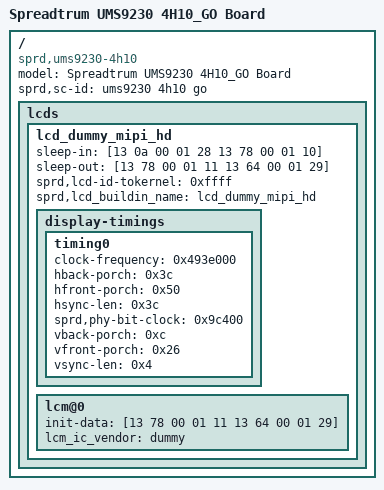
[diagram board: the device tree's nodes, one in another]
/dts-v1/;

/ {
	compatible = "sprd,ums9230-4h10";
	model = "Spreadtrum UMS9230 4H10_GO Board";
	sprd,sc-id = "ums9230 4h10 go";

	__fixups__ {
		adi_bus = "/fragment@32:target:0";
		aon_clk = "/fragment/__overlay__/sprd-marlin3:clocks:0";
		aon_i2c0 = "/fragment@8:target:0";
		aonapb_gate = "/fragment/__overlay__/sprd-marlin3:clocks:12";
		ap_gpio = "/fragment/__overlay__/gpio-keys/key-volumedown:gpios:0", "/fragment/__overlay__/audio-voice-trig:irq_gpio:0", "/fragment/__overlay__/sprd-marlin3:m2-wakeup-ap-gpios:0", "/fragment/__overlay__/sprd-marlin3:reset-gpios:0", "/fragment/__overlay__/sprd-marlin3:enable-gpios:0", "/fragment/__overlay__/sprd-marlin3:m2-to-ap-irq-gpios:0", "/fragment@4/__overlay__/sensor-main@20:dvdd-gpios:0", "/fragment@4/__overlay__/sensor-main@20:reset-gpios:0", "/fragment@4/__overlay__/sensor-main@20:power-down-gpios:0", "/fragment@4/__overlay__/sensor-sub@5a:dvdd-gpios:0", "/fragment@4/__overlay__/sensor-sub@5a:reset-gpios:0", "/fragment@4/__overlay__/sensor-sub@5a:power-down-gpios:0", "/fragment@5/__overlay__/sensor-main2@20:mot-gpios:0", "/fragment@5/__overlay__/sensor-main2@20:reset-gpios:0", "/fragment@5/__overlay__/sensor-main2@20:power-down-gpios:0", "/fragment@6/__overlay__/charger@6b:irq-gpio:0", "/fragment@6/__overlay__/charger@65:irq-gpio:0", "/fragment@6/__overlay__/charger@1b:chg_pump_en_gpio:0", "/fragment@6/__overlay__/charger@61:rx,irq_gpio:0", "/fragment@6/__overlay__/charger@61:switch_chg_en_gpio:0", "/fragment@6/__overlay__/charger@61:switch_flag_en_gpio:0", "/fragment@6/__overlay__/flash-ic@63:flash-torch-en-gpios:0", "/fragment@6/__overlay__/flash-ic@63:flash-chip-en-gpios:0", "/fragment@6/__overlay__/flash-ic@63:flash-en-gpios:0", "/fragment@6/__overlay__/flash-ic@63:flash-sync-gpios:0", "/fragment@7/__overlay__/sensor-sub2@6e:avdd-gpios:0", "/fragment@7/__overlay__/sensor-sub2@6e:mot-gpios:0", "/fragment@7/__overlay__/sensor-sub2@6e:reset-gpios:0", "/fragment@9/__overlay__/focaltech@0:focaltech,reset-gpio:0", "/fragment@9/__overlay__/focaltech@0:focaltech,irq-gpio:0", "/fragment@17/__overlay__/ucp1301@58:reset-gpios:0", "/fragment@19/__overlay__/ucp1301@58:reset-gpios:0", "/fragment@20/__overlay__:mic-gpios:0", "/fragment@20/__overlay__:lr-gpios:0", "/fragment@25/__overlay__:avdd-gpio:0", "/fragment@25/__overlay__:avee-gpio:0", "/fragment@25/__overlay__:reset-gpio:0";
		chosen = "/fragment@1:target:0";
		csi0 = "/fragment@4/__overlay__/sensor-main@20:csi:0", "/fragment@4/__overlay__/sensor-sub@5a:csi:0";
		csi1 = "/fragment@5/__overlay__/sensor-main2@20:csi:0";
		csi2 = "/fragment@7/__overlay__/sensor-sub2@6e:csi:0";
		ddr_dfs = "/fragment@29:target:0";
		dpu = "/fragment@26:target:0";
		dvfs_dcdc_cpu0_supply = "/fragment@10:target:0";
		dvfs_dcdc_cpu1_supply = "/fragment@11:target:0";
		eic_async = "/fragment/__overlay__/fingerprint@0:fpint-gpios:0";
		eic_sync = "/fragment@14/__overlay__:cd-gpios:0";
		ext_26m = "/fragment@4/__overlay__/sensor-main@20:clocks:40", "/fragment@4/__overlay__/sensor-sub@5a:clocks:40", "/fragment@5/__overlay__/sensor-main2@20:clocks:40", "/fragment@7/__overlay__/sensor-sub2@6e:clocks:40";
		ext_32k = "/fragment/__overlay__/sprd-marlin3:clocks:8";
		extcon_gpio = "/fragment@6/__overlay__/charger@6b:extcon:0", "/fragment@12/__overlay__:extcon:0", "/fragment@13/__overlay__:extcon:0";
		hsphy = "/fragment@6/__overlay__/charger@6b:phys:0", "/fragment@6/__overlay__/charger@61:phys:0", "/fragment@12:target:0", "/fragment@27/__overlay__:phys:0";
		i2c0 = "/fragment@4:target:0";
		i2c1 = "/fragment@5:target:0";
		i2c2 = "/fragment@17:target:0";
		i2c3 = "/fragment@18:target:0";
		i2c4 = "/fragment@19:target:0";
		i2c5 = "/fragment@6:target:0";
		i2c6 = "/fragment@7:target:0";
		ion = "/fragment@15:target:0", "/fragment@31:target:0";
		mm_clk = "/fragment@4/__overlay__/sensor-main@20:clocks:0", "/fragment@4/__overlay__/sensor-sub@5a:clocks:0", "/fragment@5/__overlay__/sensor-main2@20:clocks:0", "/fragment@7/__overlay__/sensor-sub2@6e:clocks:0";
		mm_gate = "/fragment@4/__overlay__/sensor-main@20:clocks:8", "/fragment@4/__overlay__/sensor-sub@5a:clocks:8", "/fragment@5/__overlay__/sensor-main2@20:clocks:8", "/fragment@7/__overlay__/sensor-sub2@6e:clocks:8";
		panel = "/fragment@25:target:0";
		pdm_dmic = "/fragment@21:target:0", "/fragment@22/__overlay__/sprd-audio-card,dai-link@81/codec:sound-dai:0";
		pin_controller = "/fragment@30:target:0";
		pll1 = "/fragment@4/__overlay__/sensor-main@20:clocks:16", "/fragment@4/__overlay__/sensor-main@20:clocks:24", "/fragment@4/__overlay__/sensor-main@20:clocks:32", "/fragment@4/__overlay__/sensor-sub@5a:clocks:16", "/fragment@4/__overlay__/sensor-sub@5a:clocks:24", "/fragment@4/__overlay__/sensor-sub@5a:clocks:32", "/fragment@5/__overlay__/sensor-main2@20:clocks:16", "/fragment@5/__overlay__/sensor-main2@20:clocks:24", "/fragment@5/__overlay__/sensor-main2@20:clocks:32", "/fragment@7/__overlay__/sensor-sub2@6e:clocks:16", "/fragment@7/__overlay__/sensor-sub2@6e:clocks:24", "/fragment@7/__overlay__/sensor-sub2@6e:clocks:32";
		pmic_adc = "/fragment/__overlay__/thermal-sensor:io-channels:0", "/fragment/__overlay__/pa-sensor:io-channels:0", "/fragment/__overlay__/chg-sensor:io-channels:0";
		pmic_eic = "/fragment/__overlay__/gpio-keys/key-volumeup:gpios:0", "/fragment/__overlay__/gpio-keys/key-power:gpios:0";
		pmic_fchg = "/fragment@27:target:0";
		pmic_fgu = "/fragment@24:target:0";
		pmic_pd = "/fragment@6/__overlay__/charger@6b:extcon:4", "/fragment@28:target:0";
		pmic_typec = "/fragment/__overlay__/charger-manager/regulator@0/cable@0:extcon:0", "/fragment@13/__overlay__:extcon:4", "/fragment@20/__overlay__:extcon:0";
		pwms = "/fragment/__overlay__/sprd_backlight:pwms:0";
		reserved_memory = "/fragment@2:target:0";
		sdio0 = "/fragment@14:target:0";
		sdio1 = "/fragment/__overlay__/sprd-marlin3:sdhci-name:0", "/fragment@0:target:0";
		sound_vbc_v4_sprd_codec = "/fragment@22:target:0";
		spi3 = "/fragment@9:target:0";
		sprd_headset = "/fragment@20:target:0";
		sprd_route_pcm = "/fragment@22/__overlay__/sprd-audio-card,dai-link@53/plat:sound-dai:0", "/fragment@22/__overlay__/sprd-audio-card,dai-link@55/plat:sound-dai:0", "/fragment@22/__overlay__/sprd-audio-card,dai-link@81/plat:sound-dai:0";
		thm_zone = "/fragment@3:target:0";
		ufs = "/fragment@16:target:0";
		uid_end = "/fragment/__overlay__/sprd_uid:nvmem-cells:4";
		uid_start = "/fragment/__overlay__/sprd_uid:nvmem-cells:0";
		usb = "/fragment@13:target:0";
		vbc_v4 = "/fragment@22/__overlay__/sprd-audio-card,dai-link@53/cpu:sound-dai:0", "/fragment@22/__overlay__/sprd-audio-card,dai-link@55/cpu:sound-dai:0", "/fragment@22/__overlay__/sprd-audio-card,dai-link@81/cpu:sound-dai:0";
		vddcama0 = "/fragment@4/__overlay__/sensor-main@20:vddcama-supply:0", "/fragment@4/__overlay__/sensor-sub@5a:vddcama-supply:0";
		vddcama1 = "/fragment@5/__overlay__/sensor-main2@20:vddcama-supply:0";
		vddcamd0 = "/fragment@5/__overlay__/sensor-main2@20:vddcamd-supply:0";
		vddcamd1 = "/fragment@7/__overlay__/sensor-sub2@6e:vddcamd-supply:0";
		vddcamio = "/fragment@4/__overlay__/sensor-main@20:vddio-supply:0", "/fragment@4/__overlay__/sensor-sub@5a:vddio-supply:0", "/fragment@5/__overlay__/sensor-main2@20:vddio-supply:0", "/fragment@7/__overlay__/sensor-sub2@6e:vddio-supply:0";
		vddcammot = "/fragment@4/__overlay__/sensor-main@20:vddcammot-supply:0", "/fragment@4/__overlay__/sensor-sub@5a:vddcammot-supply:0", "/fragment@5/__overlay__/sensor-main2@20:vddcammot-supply:0", "/fragment@7/__overlay__/sensor-sub2@6e:vddcammot-supply:0";
		vddldo0 = "/fragment@23:target:0";
		vddsim2 = "/fragment/__overlay__/sprd-marlin3:dcxo18-supply:0";
		vddusb33 = "/fragment@12/__overlay__:vdd-supply:0";
		vddwcn = "/fragment/__overlay__/sprd-marlin3:avdd12-supply:0";
		vddwifipa = "/fragment/__overlay__/sprd-marlin3:avdd33-supply:0";
	};

	__local_fixups__ {

		fragment {

			__overlay__ {

				charger-manager {
					monitored-battery = <0x0>;
				};

				lcds {

					lcd_g40396_truly_mipi_fhd {

						display-timings {
							native-mode = <0x0>;
						};
					};
				};
			};
		};

		fragment@13 {

			__overlay__ {
				vbus-supply = <0x0>;
			};
		};

		fragment@15 {

			__overlay__ {

				heap@3 {
					memory-region = <0x0>;
				};
			};
		};

		fragment@22 {

			__overlay__ {

				sprd-audio-card,dai-link@53 {

					codec {
						sound-dai = <0x0>;
					};
				};

				sprd-audio-card,dai-link@55 {

					codec {
						sound-dai = <0x0>;
					};
				};
			};
		};

		fragment@24 {

			__overlay__ {
				monitored-battery = <0x0>;
			};
		};

		fragment@25 {

			__overlay__ {
				sprd,backlight = <0x0>;
			};
		};

		fragment@26 {

			__overlay__ {
				sprd,backlight = <0x0>;
				sprd,logo-memory = <0x0>;
				sprd,wb-memory = <0x0>;
			};
		};

		fragment@3 {

			__overlay__ {

				board-thmzone {
					thermal-sensors = <0x0>;
				};

				chg-thmzone {
					thermal-sensors = <0x0>;
				};

				pa-thmzone {
					thermal-sensors = <0x0>;
				};
			};
		};

		fragment@30 {

			__overlay__ {
				pinctrl-0 = <0x0>;
				pinctrl-1 = <0x0>;
				pinctrl-2 = <0x0>;
				pinctrl-3 = <0x0>;
				pinctrl-4 = <0x0>;
				pinctrl-5 = <0x0>;
				pinctrl-6 = <0x0>;
			};
		};

		fragment@31 {

			__overlay__ {

				heap@4 {
					memory-region = <0x0>;
				};
			};
		};

		fragment@6 {

			__overlay__ {

				charger@6b {
					monitored-battery = <0x0>;
				};
			};
		};
	};

	__symbols__ {
		bat = "/fragment/__overlay__/battery";
		bd_thmzone = "/fragment@3/__overlay__/board-thmzone";
		bq2560x_chg = "/fragment@6/__overlay__/charger@6b";
		bq2597x_chg = "/fragment@6/__overlay__/charger@65";
		chg_thermistor = "/fragment/__overlay__/chg-sensor";
		chg_thmzone = "/fragment@3/__overlay__/chg-thmzone";
		fb_reserved = "/fragment@2/__overlay__/framebuffer-mem@fe980000";
		fd_reserved = "/fragment@2/__overlay__/faceid-mem@fd9a0000";
		flash_ic = "/fragment@6/__overlay__/flash-ic@63";
		g40396_truly_timing0 = "/fragment/__overlay__/lcds/lcd_g40396_truly_mipi_fhd/display-timings/timing0";
		gpio_124 = "/fragment@30/__overlay__/keyin0";
		gpio_175 = "/fragment@30/__overlay__/bt_rfctl2";
		gpio_22 = "/fragment@30/__overlay__/rfctl3";
		gpio_24 = "/fragment@30/__overlay__/rfctl5";
		gpio_25 = "/fragment@30/__overlay__/rfctl6";
		gpio_26 = "/fragment@30/__overlay__/rfctl7";
		gpio_8 = "/fragment@30/__overlay__/rfctl16";
		hl1506_cp_converter = "/fragment@6/__overlay__/charger@1b";
		lcd_dummy_mipi_hd = "/lcds/lcd_dummy_mipi_hd";
		lcd_dummy_timing0 = "/lcds/lcd_dummy_mipi_hd/display-timings/timing0";
		lcd_g40396_truly_mipi_fhd = "/fragment/__overlay__/lcds/lcd_g40396_truly_mipi_fhd";
		logo_reserved = "/fragment@2/__overlay__/logobuffer@9e000000";
		nu1619_rx = "/fragment@6/__overlay__/charger@61";
		pa_thermistor = "/fragment/__overlay__/pa-sensor";
		pa_thmzone = "/fragment@3/__overlay__/pa-thmzone";
		pwm_backlight = "/fragment/__overlay__/sprd_backlight";
		sensor_main = "/fragment@4/__overlay__/sensor-main@20";
		sensor_main2 = "/fragment@5/__overlay__/sensor-main2@20";
		sensor_sub = "/fragment@4/__overlay__/sensor-sub@5a";
		sensor_sub2 = "/fragment@7/__overlay__/sensor-sub2@6e";
		sprd_marlin3 = "/fragment/__overlay__/sprd-marlin3";
		tboard_thermistor = "/fragment/__overlay__/thermal-sensor";
		ucp1301_rcv = "/fragment@17/__overlay__/ucp1301@58";
		ucp1301_spk = "/fragment@19/__overlay__/ucp1301@58";
		usb_con = "/fragment@28/__overlay__/connector";
		vddvbus = "/fragment@6/__overlay__/charger@6b/otg-vbus";
		wb_reserved = "/fragment@2/__overlay__/writeback-mem@fdea0000";
	};

	fragment {
		target-path = [2f 00];

		__overlay__ {

			audio-voice-trig {
				compatible = "sprd,voice_trig";
				irq_gpio = <0xffffffff 0xa9 0x0>;
				status = "disable";
			};

			battery {
				capacity-temp-table = <0x2d 0x64 0x19 0x64 0xa 0x64 0x0 0x5f 0xfffffff6 0x5a>;
				charge-cdp-current-microamp = <0x16e360 0x16e360>;
				charge-dcp-current-microamp = <0x1e8480 0x2dc6c0>;
				charge-fchg-current-microamp = <0x319750 0x2dc6c0>;
				charge-flash-current-microamp = <0x4c4b40 0x2932e0>;
				charge-full-design-microamp-hours = <0x2d0370>;
				charge-pumps-threshold-microvolt = <0x3e8fa0>;
				charge-sdp-current-microamp = <0x7a120 0x7a120>;
				charge-term-current-microamp = <0xea60>;
				charge-unknown-current-microamp = <0x7a120 0x7a120>;
				charge-wl-bpp-current-microamp = <0xf4240 0xf4240>;
				charge-wl-epp-current-microamp = <0x1e8480 0xf4240>;
				compatible = "simple-battery";
				constant_charge_voltage_max_microvolt = <0x423920>;
				factory-internal-resistance-micro-ohms = <0x3d860>;
				ocv-capacity-celsius = <0x14>;
				ocv-capacity-table-0 = <0x41cfa8 0x64 0x40e930 0x5f 0x401a28 0x5a 0x3f56d8 0x55 0x3e9770 0x50 0x3df360 0x4b 0x3d2070 0x46 0x3c9f88 0x41 0x3bf790 0x3c 0x3b3c10 0x37 0x3ac2f8 0x32 0x3a6d08 0x2d 0x3a22d0 0x28 0x39e838 0x23 0x39b188 0x1e 0x397308 0x19 0x3928d0 0x14 0x38cb10 0xf 0x385db0 0xa 0x382ed0 0x5 0x33e140 0x0>;
				phandle = <0x2>;
				resistance-temp-table = <0x2d 0x35 0x19 0x64 0xa 0x18b 0x0 0x237 0xfffffff6 0x319>;
				voltage-min-design-microvolt = <0x34a490>;
				voltage-temp-table = <0x108a60 0x320 0xee098 0x352 0xd3ea0 0x384 0xbac48 0x3b6 0xa3160 0x3e8 0x8d9a0 0x41a 0x7a508 0x44c 0x68fb0 0x47e 0x5a168 0x4b0 0x4ce78 0x4e2 0x41eb0 0x514 0x38658 0x546 0x30188 0x578 0x29428 0x5aa 0x23668 0x5dc 0x1e848 0x60e 0x1a5e0 0x640 0x16b48 0x672>;
			};

			charger-manager {
				cm-battery-cold = <0xc8>;
				cm-battery-cold-in-minus;
				cm-battery-hot = <0x320>;
				cm-battery-stat = <0x2>;
				cm-battery-temp-diff = <0x64>;
				cm-cap-remap-table = <0x1 0x2 0x3 0x2 0x3 0x2 0x62 0x63 0x2 0x63 0x64 0x3>;
				cm-capacity-track;
				cm-cdp-jeita-temp-table = <0x3e8 0x406 0x0 0x423920 0x47e 0x49c 0xaae60 0x423920 0x5aa 0x58c 0x16e360 0x423920 0x640 0x622 0xaae60 0x3e8fa0>;
				cm-charge-pumps = "bq2597x-standalone";
				cm-charge-voltage-drop = <0xaae60>;
				cm-charge-voltage-max = <0x632ea0>;
				cm-chargers = "bq2560x_charger";
				cm-charging-max = <0x1499700>;
				cm-cp-taper-current = <0xf4240>;
				cm-dcp-jeita-temp-table = <0x3e8 0x406 0x0 0x423920 0x47e 0x49c 0xaae60 0x423920 0x5aa 0x58c 0x1e8480 0x423920 0x640 0x622 0xaae60 0x3e8fa0>;
				cm-discharging-max = <0x2932e0>;
				cm-fast-charge-voltage-drop = <0xaae60>;
				cm-fast-charge-voltage-max = <0xa037a0>;
				cm-fast-chargers = "sc2730_fast_charger";
				cm-fchg-jeita-temp-table = <0x3e8 0x406 0x0 0x423920 0x47e 0x49c 0xaae60 0x423920 0x5aa 0x58c 0x319750 0x423920 0x640 0x622 0xaae60 0x3e8fa0>;
				cm-flash-charge-voltage-drop = <0xf4240>;
				cm-flash-charge-voltage-max = <0xb71b00>;
				cm-flash-jeita-temp-table = <0x3e8 0x406 0x0 0x423920 0x47e 0x49c 0xf4240 0x423920 0x5aa 0x58c 0x4c4b40 0x423920 0x640 0x622 0xf4240 0x3e8fa0>;
				cm-fuel-gauge = "sc27xx-fgu";
				cm-fullbatt-capacity = <0x64>;
				cm-fullbatt-current = <0x1d4c0>;
				cm-fullbatt-vchkdrop-ms = <0x7530>;
				cm-fullbatt-vchkdrop-volt = <0xea60>;
				cm-fullbatt-voltage = <0x419ce0>;
				cm-ir-cv-offset-microvolt = <0x186a0>;
				cm-ir-rc = <0x14>;
				cm-ir-us-upper-limit-microvolt = <0x44aa20>;
				cm-name = "battery";
				cm-num-charge-pumps = <0x1>;
				cm-num-chargers = <0x1>;
				cm-num-fast-chargers = <0x1>;
				cm-num-wireless-charge-pump-converters = <0x1>;
				cm-num-wireless-chargers = <0x1>;
				cm-one-cap-time = <0x1e>;
				cm-poll-interval = <0x3a98>;
				cm-poll-mode = <0x2>;
				cm-sdp-jeita-temp-table = <0x3e8 0x406 0x0 0x423920 0x47e 0x49c 0x7a120 0x423920 0x5aa 0x58c 0x7a120 0x423920 0x640 0x622 0x7a120 0x3e8fa0>;
				cm-shutdown-voltage = <0x2f4d60>;
				cm-tickle-time-out = <0x5dc>;
				cm-unknown-jeita-temp-table = <0x3e8 0x406 0x0 0x423920 0x47e 0x49c 0x7a120 0x423920 0x5aa 0x58c 0x7a120 0x423920 0x640 0x622 0x7a120 0x3e8fa0>;
				cm-wdt-interval = <0x3c>;
				cm-wireless-charge-pump-converters = "hl1506_cp_converter";
				cm-wireless-charge-voltage-drop = <0xaae60>;
				cm-wireless-charge-voltage-max = <0x632ea0>;
				cm-wireless-chargers = "nu1619_wireless_charger";
				cm-wireless-fast-charge-voltage-drop = <0xf4240>;
				cm-wireless-fast-charge-voltage-max = <0xb71b00>;
				cm-wl-bpp-jeita-temp-table = <0x3e8 0x406 0x0 0x423920 0x47e 0x49c 0x7a120 0x423920 0x5aa 0x58c 0xf4240 0x423920 0x640 0x622 0x4c4b40 0x3e8fa0>;
				cm-wl-epp-jeita-temp-table = <0x3e8 0x406 0x0 0x423920 0x47e 0x49c 0x7a120 0x423920 0x5aa 0x58c 0x1e8480 0x423920 0x640 0x622 0x7a120 0x3e8fa0>;
				compatible = "charger-manager";
				monitored-battery = <0x2>;

				regulator@0 {
					cm-regulator-name = "vddgen0";

					cable@0 {
						cm-cable-name = "USB";
						extcon = <0xffffffff>;
					};
				};
			};

			chg-sensor {
				#thermal-sensor-cells = <0x0>;
				compatible = "generic-adc-thermal";
				io-channel-names = "sensor-channel";
				io-channels = <0xffffffff 0x4>;
				phandle = <0x5>;
				temperature-lookup-table = <0xffff64c2 0x46b 0xffff8baf 0x456 0xffffb3e8 0x432 0xffffedb9 0x3d7 0x277e 0x346 0x60e5 0x28e 0xaf7a 0x19d 0xd677 0x13c 0xfd7f 0xee 0x12484 0xb2 0x14b93 0x85 0x172a3 0x64 0x199b0 0x4b 0x1c0c9 0x39 0x1e7c8 0x2b>;
			};

			fingerprint@0 {
				compatible = "microarray,afs121";
				fpint-gpios = <0xffffffff 0x1d 0x0>;
			};

			gnss_common_ctl {
				compatible = "sprd,gnss_common_ctl";
				sprd,name = "gnss_common_ctl";
			};

			gpio-keys {
				compatible = "gpio-keys";

				key-power {
					debounce-interval = <0x2>;
					gpios = <0xffffffff 0x1 0x1>;
					label = "Power Key";
					linux,code = <0x74>;
					wakeup-source;
				};

				key-volumedown {
					debounce-interval = <0x2>;
					gpios = <0xffffffff 0x7c 0x1>;
					label = "Volume Down Key";
					linux,code = <0x72>;
					wakeup-source;
				};

				key-volumeup {
					debounce-interval = <0x2>;
					gpios = <0xffffffff 0x4 0x0>;
					label = "Volume Up Key";
					linux,code = <0x73>;
					wakeup-source;
				};
			};

			lcds {

				lcd_g40396_truly_mipi_fhd {
					phandle = <0x15>;
					sprd,dpi-clk-div = <0x6>;
					sprd,dsi-color-format = "rgb888";
					sprd,dsi-lane-number = <0x4>;
					sprd,dsi-work-mode = <0x1>;
					sprd,esd-check-enable = <0x1>;
					sprd,esd-check-mode = <0x0>;
					sprd,esd-check-period = <0x7d0>;
					sprd,esd-check-regs = <0xa>;
					sprd,esd-return-code = <0x9c>;
					sprd,height-mm = <0x98>;
					sprd,hporch-lp-disable = <0x1>;
					sprd,initial-command = [29 00 00 02 00 00 29 00 00 04 ff 87 56 01 29 00 00 02 00 80 29 00 00 03 ff 87 56 29 00 00 02 00 a1 29 00 00 07 b3 04 38 09 60 00 fc 29 00 00 02 00 80 29 00 00 07 c0 00 8c 00 20 00 08 29 00 00 02 00 90 29 00 00 07 c0 00 8c 00 20 00 08 29 00 00 02 00 a0 29 00 00 07 c0 01 19 00 20 00 08 29 00 00 02 00 b0 29 00 00 06 c0 00 8c 00 20 08 29 00 00 02 00 c1 29 00 00 09 c0 00 d0 00 9f 00 8b 00 ee 29 00 00 02 00 d7 29 00 00 07 c0 00 8b 00 20 00 08 29 00 00 02 00 a3 29 00 00 07 c1 00 3e 00 3e 00 02 29 00 00 02 00 80 29 00 00 11 ce 01 81 09 13 00 d0 00 e8 00 82 00 9a 00 68 00 74 29 00 00 02 00 90 29 00 00 10 ce 00 8e 0c df 00 8e 80 09 13 00 04 00 08 08 08 29 00 00 02 00 a0 29 00 00 04 ce 00 00 00 29 00 00 02 00 b0 29 00 00 04 ce 22 00 00 29 00 00 02 00 d1 29 00 00 08 ce 00 00 01 00 00 00 00 29 00 00 02 00 e1 29 00 00 0c ce 08 02 4d 02 4d 02 4d 00 00 00 00 29 00 00 02 00 f1 29 00 00 0a ce 13 09 0d 00 f6 01 96 00 c2 29 00 00 02 00 b0 29 00 00 05 cf 00 00 68 6c 29 00 00 02 00 b5 29 00 00 05 cf 04 04 e4 e8 29 00 00 02 00 c0 29 00 00 05 cf 09 09 2c 30 29 00 00 02 00 c5 29 00 00 05 cf 00 00 08 0c 29 00 00 02 00 e8 29 00 00 02 c0 40 29 00 00 02 00 80 29 00 00 05 c2 84 01 3f 3f 29 00 00 02 00 90 29 00 00 05 c2 02 01 00 00 29 00 00 02 00 a0 29 00 00 10 c2 84 04 00 00 8a 83 04 00 00 8a 82 04 00 00 8a 29 00 00 02 00 b0 29 00 00 06 c2 81 04 00 00 8a 29 00 00 02 00 e0 29 00 00 0f c2 33 33 33 33 33 33 00 00 12 00 05 02 00 00 29 00 00 02 00 c0 29 00 00 05 c3 99 99 99 99 29 00 00 02 00 d0 29 00 00 0d c3 45 00 00 05 45 00 00 05 45 00 00 05 29 00 00 02 00 80 29 00 00 11 cb c1 c1 00 c1 c1 00 00 c1 fe 01 c1 00 fd c1 00 c0 29 00 00 02 00 90 29 00 00 11 cb c0 00 00 00 00 00 00 00 ff 00 00 00 00 00 00 00 29 00 00 02 00 a0 29 00 00 05 cb 00 00 00 00 29 00 00 02 00 b0 29 00 00 05 cb 55 55 95 55 29 00 00 02 00 c0 29 00 00 05 cb 10 51 94 50 29 00 00 02 00 80 29 00 00 11 cc 00 00 00 25 25 29 16 17 18 19 1a 1b 22 24 06 06 29 00 00 02 00 90 29 00 00 09 cc 08 08 24 02 12 01 29 29 29 00 00 02 00 80 29 00 00 11 cd 00 00 00 25 25 29 16 17 18 19 1a 1b 22 24 07 07 29 00 00 02 00 90 29 00 00 09 cd 09 09 24 02 12 01 29 29 29 00 00 02 00 a0 29 00 00 11 cc 00 00 00 25 25 29 16 17 18 19 1a 1b 24 23 09 09 29 00 00 02 00 b0 29 00 00 09 cc 07 07 24 12 02 01 29 29 29 00 00 02 00 a0 29 00 00 11 cd 00 00 00 25 25 29 16 17 18 19 1a 1b 24 23 08 08 29 00 00 02 00 b0 29 00 00 09 cd 06 06 24 12 02 01 29 29 29 00 00 02 00 80 29 00 00 02 a7 10 29 00 00 02 00 82 29 00 00 03 a7 33 02 29 00 00 02 00 85 29 00 00 02 a7 10 29 00 00 02 00 85 29 00 00 02 c4 1c 29 00 00 02 00 97 29 00 00 02 c4 01 29 00 00 02 00 a0 29 00 00 04 c4 2d d2 2d 29 00 00 02 00 93 29 00 00 02 c5 29 29 00 00 02 00 97 29 00 00 02 c5 29 29 00 00 02 00 9a 29 00 00 02 c5 23 29 00 00 02 00 9c 29 00 00 02 c5 23 29 00 00 02 00 b6 29 00 00 03 c5 1f 1f 29 00 00 02 00 b8 29 00 00 03 c5 19 19 29 00 00 02 00 9b 29 00 00 02 f5 4b 29 00 00 02 00 93 29 00 00 03 f5 00 00 29 00 00 02 00 9d 29 00 00 02 f5 49 29 00 00 02 00 82 29 00 00 03 f5 00 00 29 00 00 02 00 8c 29 00 00 04 c3 00 00 00 29 00 00 02 00 84 29 00 00 03 c5 28 28 29 00 00 02 00 a4 29 00 00 02 d7 00 29 00 00 02 00 80 29 00 00 03 f5 59 59 29 00 00 02 00 84 29 00 00 04 f5 59 59 59 29 00 00 02 00 96 29 00 00 02 f5 59 29 00 00 02 00 a6 29 00 00 02 f5 59 29 00 00 02 00 ca 29 00 00 02 c0 80 29 00 00 02 00 b1 29 00 00 02 f5 1f 29 00 00 02 00 00 29 00 00 03 d8 2f 2f 29 00 00 02 00 00 29 00 00 03 d9 23 23 29 00 00 02 00 86 29 00 00 07 c0 01 04 01 04 0e 03 29 00 00 02 00 96 29 00 00 07 c0 01 04 01 04 0d 03 29 00 00 02 00 a6 29 00 00 07 c0 01 04 01 04 18 03 29 00 00 02 00 e9 29 00 00 07 c0 01 04 01 04 0d 03 29 00 00 02 00 a3 29 00 00 07 ce 01 04 01 04 0d 03 29 00 00 02 00 b3 29 00 00 07 ce 01 04 01 04 0d 03 29 00 00 02 00 a0 29 00 00 02 d7 04 29 00 00 02 00 00 29 00 00 29 e1 00 04 08 0f 1a 1a 22 28 33 5c 3b 42 48 4d 1b 53 5b 63 6a 2b 72 79 81 8a 3a 95 9b a1 a9 0a b2 bd cb d4 6b e0 ee fa ff 17 29 00 00 02 00 00 29 00 00 29 e2 00 04 08 0f 1a 1a 22 28 33 5c 3b 42 48 4e 18 53 5b 63 6b 28 72 79 81 8a 2a 94 9b a1 a9 ca b2 bd cb d5 68 e0 ee fa ff 67 29 00 00 02 00 00 29 00 00 29 e3 00 03 07 0e 3f 19 21 27 31 46 39 40 47 4c b2 51 5a 61 69 8d 70 77 7f 88 68 92 97 9d a5 2c ad b7 c3 cb 58 d4 df e6 ea 7b 29 00 00 02 00 00 29 00 00 29 e4 00 03 07 0e 3f 19 21 27 31 45 39 40 47 4c b1 51 59 61 69 bd 70 77 7f 87 67 91 97 9d a5 ec ad b7 c3 cb 49 d4 e0 e6 ea 4b 29 00 00 02 00 00 29 00 00 29 e5 00 03 08 0e 33 19 20 27 31 31 39 41 47 4c 87 51 5a 62 69 d6 70 77 7f 88 b8 92 97 9e a5 32 ae b8 c5 ce 2c d8 e6 f0 f5 f6 29 00 00 02 00 00 29 00 00 29 e6 00 03 08 0e 33 19 20 27 31 31 39 41 47 4c 87 51 5a 62 69 d2 70 77 7f 88 b8 92 97 9e a5 32 ae b8 c5 ce 2d d9 e7 f0 f5 06 29 00 00 02 00 cc 29 00 00 02 c0 10 29 00 00 02 00 00 29 00 00 04 ff ff ff ff 15 00 00 02 35 00 15 00 00 02 51 ff 15 00 00 02 53 24 15 00 00 02 55 00 05 78 00 01 11 05 32 00 01 29 15 01 00 02 b0 00 15 01 00 02 b1 01];
					sprd,phy-bit-clock = <0x104be0>;
					sprd,phy-escape-clock = <0x4e20>;
					sprd,power-gpio-delay = <0x14>;
					sprd,reset-off-sequence = <0x0 0x5>;
					sprd,reset-on-sequence = <0x1 0x5 0x0 0x5 0x1 0x14>;
					sprd,sleep-in-command = <0x15000002 0x3900 0x4ff87 0x56011500 0x20080 0x39000003 0xff875605 0x32000128 0x5780001 0x10150000 0x2000039 0x5f7 0x5aa59527>;
					sprd,sleep-out-command = [15 78 00 01 11 15 32 00 01 29 15 01 00 02 b0 00 15 01 00 02 b1 01];
					sprd,use-dcs-write;
					sprd,video-lp-cmd-enable = <0x1>;
					sprd,width-mm = <0x44>;

					display-timings {
						native-mode = <0x1>;

						timing0 {
							clock-frequency = <0xa9c1080>;
							hactive = <0x438>;
							hback-porch = <0x20>;
							hfront-porch = <0x30>;
							hsync-len = <0x10>;
							phandle = <0x1>;
							vactive = <0x960>;
							vback-porch = <0x20>;
							vfront-porch = <0x5b>;
							vsync-len = <0x4>;
						};
					};
				};
			};

			pa-sensor {
				#thermal-sensor-cells = <0x0>;
				compatible = "generic-adc-thermal";
				io-channel-names = "sensor-channel";
				io-channels = <0xffffffff 0x2>;
				phandle = <0x4>;
				temperature-lookup-table = <0xffff64c2 0x46b 0xffff8baf 0x456 0xffffb3e8 0x432 0xffffedb9 0x3d7 0x277e 0x346 0x60e5 0x28e 0xaf7a 0x19d 0xd677 0x13c 0xfd7f 0xee 0x12484 0xb2 0x14b93 0x85 0x172a3 0x64 0x199b0 0x4b 0x1c0c9 0x39 0x1e7c8 0x2b>;
			};

			sprd-fm {
				compatible = "sprd,marlin3-fm";
				sprd,name = "sprd-fm";
			};

			sprd-marlin3 {
				adma-rx;
				adma-tx;
				avdd12-bound-wbreq = <0x1ac8 0x1000 0x0 0x1000>;
				avdd12-parent-bound-chip = <0x1a4c 0x1 0x0 0x1>;
				avdd12-supply = <0xffffffff>;
				avdd33-bound-wbreq = <0x1acc 0x4 0x0 0x4>;
				avdd33-supply = <0xffffffff>;
				clock-names = "clk_32k", "source", "enable";
				clocks = <0xffffffff 0x4 0xffffffff 0xffffffff 0x6>;
				compatible = "sprd,marlin3";
				dcxo18-supply = <0xffffffff>;
				enable-gpios = <0xffffffff 0x74 0x1>;
				m2-to-ap-irq-gpios = <0xffffffff 0x34 0x1>;
				m2-wakeup-ap-gpios = <0xffffffff 0x35 0x1>;
				phandle = <0x16>;
				reset-gpios = <0xffffffff 0xb1 0x1>;
				sdhci-name = <0xffffffff>;
				sprd,btwf-file-name = "/dev/block/by-name/wcnmodem";
				sprd,gnss-file-name = "/dev/block/by-name/gnssmodem";
			};

			sprd-mtty {
				compatible = "sprd,mtty";
				sprd,name = "ttyBT";
			};

			sprd-wlan {
				compatible = "sprd,sc2355-wifi";
			};

			sprd_backlight {
				compatible = "sprd,sharkl6-backlight";
				default-brightness-level = <0x106>;
				phandle = <0xa>;
				pwm-names = "backlight";
				pwms = <0xffffffff 0x2 0x9c40>;
				sprd,brightness-scale = <0xfff>;
				sprd,max-brightness-level = <0x39c>;
			};

			sprd_uid {
				compatible = "sprd-uid";
				nvmem-cell-names = "uid_start", "uid_end";
				nvmem-cells = <0xffffffff 0xffffffff>;
			};

			thermal-sensor {
				#thermal-sensor-cells = <0x0>;
				compatible = "generic-adc-thermal";
				io-channel-names = "sensor-channel";
				io-channels = <0xffffffff 0x1>;
				phandle = <0x3>;
				temperature-lookup-table = <0xffff64c2 0x46b 0xffff8baf 0x456 0xffffb3e8 0x432 0xffffedb9 0x3d7 0x277e 0x346 0x60e5 0x28e 0xaf7a 0x19d 0xd677 0x13c 0xfd7f 0xee 0x12484 0xb2 0x14b93 0x85 0x172a3 0x64 0x199b0 0x4b 0x1c0c9 0x39 0x1e7c8 0x2b>;
			};
		};
	};

	fragment@0 {
		target = <0xffffffff>;

		__overlay__ {
			bus-width = <0x4>;
			no-mmc;
			no-sd;
			sd-uhs-sdr104;
			sd-uhs-sdr50;
			sprd,name = "sdio_wifi";
			sprd,sdio-adma;
			sprd,sdr104-dly = <0x7f 0x7f 0x7f 0x7f>;
			sprd,sdr50-dly = <0x7f 0x7f 0x8f 0x8f>;
			status = "okay";
		};
	};

	fragment@1 {
		target = <0xffffffff>;

		__overlay__ {
			bootargs_ext = "androidboot.hardware=ums9230_4h10_go androidboot.dtbo_idx=0";
		};
	};

	fragment@10 {
		target = <0xffffffff>;

		__overlay__ {
			chnl-in-i2c = <0x0>;
			pmic-type-num = <0x0>;
			slew-rate = <0x249f>;
			top-dvfs-adi-state = <0x70 0x0 0xf>;
			tuning-latency-us = <0x0>;
			voltage-down-delay = <0x32 0x64 0x0 0xffff 0x600 0x64 0x64 0x10 0xffff 0xa00 0x96 0x60 0x0 0xffff 0xf00 0xc8 0x60 0x10 0xffff 0x1400 0xfa 0x5c 0x0 0xffff 0x1900 0x12c 0x5c 0x10 0xffff 0x1e00 0x15e 0x114 0x0 0xffff 0x2300>;
			voltage-grade = <0x0 0xf0 0xf4 0x0 0x1ff 0x1 0xf0 0xf4 0x9 0x1ff 0x2 0x100 0xf4 0x12 0x1ff 0x3 0x110 0xf8 0x0 0x1ff 0x4 0x120 0xf8 0x9 0x1ff 0x5 0x130 0xf8 0x12 0x1ff 0x6 0x140 0xfc 0x0 0x1ff 0x7 0x140 0xfc 0x9 0x1ff>;
			voltage-grade-num = <0x8>;
			voltage-up-delay = <0x32 0x58 0x0 0xffff 0x600 0x64 0x58 0x10 0xffff 0xa00 0x96 0x54 0x0 0xffff 0xf00 0xc8 0x54 0x10 0xffff 0x1400 0xfa 0x50 0x0 0xffff 0x1900 0x12c 0x50 0x10 0xffff 0x1e00 0x15e 0x110 0x0 0xffff 0x2300>;
		};
	};

	fragment@11 {
		target = <0xffffffff>;

		__overlay__ {
			chnl-i2c-used;
			chnl-in-i2c = <0x1>;
			pmic-type-num = <0x2>;
			slew-rate = <0xfa0>;
			supply-type-sel = <0x120 0x0 0x1>;
			third-pmic-used;
			top-dvfs-i2c-state = <0x9c 0x4 0x1f>;
			tuning-latency-us = <0x0>;
			voltage-down-delay = <0x32 0x90 0x0 0xffff 0x600 0x64 0x90 0x10 0xffff 0xa00 0x96 0x8c 0x0 0xffff 0xf00 0xc8 0x8c 0x10 0xffff 0x1400 0xfa 0x88 0x0 0xffff 0x1900 0x12c 0x88 0x10 0xffff 0x1e00 0x15e 0x11c 0x0 0xffff 0x2300>;
			voltage-grade = <0x0 0x8f 0x12c 0x0 0xff 0x1 0x94 0x12c 0x8 0xff 0x2 0x99 0x12c 0x10 0xff 0x3 0x9e 0x12c 0x18 0xff 0x4 0xa3 0x130 0x0 0xff 0x5 0xa8 0x130 0x8 0xff 0x6 0xa8 0x130 0x10 0xff 0x7 0xa8 0x130 0x18 0xff>;
			voltage-grade-num = <0x8>;
			voltage-up-delay = <0x32 0x84 0x0 0xffff 0x1600 0x64 0x84 0x10 0xffff 0x1a00 0x96 0x80 0x0 0xffff 0x1f00 0xc8 0x80 0x10 0xffff 0x2400 0xfa 0x7c 0x0 0xffff 0x2900 0x12c 0x7c 0x10 0xffff 0x2e00 0x15e 0x118 0x0 0xffff 0x3300>;
		};
	};

	fragment@12 {
		target = <0xffffffff>;

		__overlay__ {
			extcon = <0xffffffff>;
			sprd,hsphy-device-eye-pattern = <0x4f3d1c0>;
			sprd,hsphy-host-eye-pattern = <0x4f3d1c0>;
			status = "okay";
			vdd-supply = <0xffffffff>;
		};
	};

	fragment@13 {
		target = <0xffffffff>;

		__overlay__ {
			extcon = <0xffffffff 0xffffffff>;
			status = "okay";
			vbus-supply = <0x6>;
		};
	};

	fragment@14 {
		target = <0xffffffff>;

		__overlay__ {
			cd-gpios = <0xffffffff 0x23 0x0>;
		};
	};

	fragment@15 {
		target = <0xffffffff>;

		__overlay__ {

			heap@3 {
				label = "carveout_fb";
				memory-region = <0x7>;
				reg = <0x3>;
				type = <0x2>;
			};
		};
	};

	fragment@16 {
		target = <0xffffffff>;

		__overlay__ {
			status = "okay";
		};
	};

	fragment@17 {
		target = <0xffffffff>;

		__overlay__ {
			status = "okay";

			ucp1301@58 {
				#sound-dai-cells = <0x1>;
				compatible = "sprd,ucp1301-rcv";
				phandle = <0x9>;
				reg = <0x58>;
				reset-gpios = <0xffffffff 0xac 0x0>;
			};
		};
	};

	fragment@18 {
		target = <0xffffffff>;

		__overlay__ {
			status = "okay";
		};
	};

	fragment@19 {
		target = <0xffffffff>;

		__overlay__ {
			status = "okay";

			ucp1301@58 {
				#sound-dai-cells = <0x1>;
				compatible = "sprd,ucp1301-spk";
				phandle = <0x8>;
				reg = <0x58>;
				reset-gpios = <0xffffffff 0xa7 0x0>;
			};
		};
	};

	fragment@2 {
		target = <0xffffffff>;

		__overlay__ {

			faceid-mem@fd9a0000 {
				phandle = <0x14>;
				reg = <0x0 0xfd9a0000 0x0 0x500000>;
			};

			framebuffer-mem@fe980000 {
				phandle = <0x7>;
				reg = <0x0 0xfe980000 0x0 0x1600000>;
			};

			logobuffer@9e000000 {
				phandle = <0xb>;
				reg = <0x0 0x9e000000 0x0 0xab0000>;
			};

			writeback-mem@fdea0000 {
				phandle = <0xc>;
				reg = <0x0 0xfdea0000 0x0 0xae0000>;
			};
		};
	};

	fragment@20 {
		target = <0xffffffff>;

		__overlay__ {
			extcon = <0xffffffff>;
			lr-gpios = <0xffffffff 0xae 0x0>;
			mic-gpios = <0xffffffff 0xaf 0x0>;
			sprd,3pole-adc-threshold = <0x70>;
			status = "okay";
		};
	};

	fragment@21 {
		target = <0xffffffff>;

		__overlay__ {
			status = "okay";
		};
	};

	fragment@22 {
		target = <0xffffffff>;

		__overlay__ {
			sprd-audio-card,routing = "HPMIC Pin", "HP Mic Jack", "MIC Pin", "Mic Jack", "MIC2 Pin", "Aux Mic Jack", "HeadPhone Jack", "HP Pin", "Ext Spk", "SPK Pin", "UCP1301 SPK ON", "SPK Pin", "Ext Spk", "UCP1301 SPK", "PDM DMIC2 ON", "SPK Pin", "Ext Spk", "PDM_DMIC2", "DMIC Pin", "DMic Jack", "DMIC1 Pin", "DMic1 Jack", "Ext Ear", "EAR Pin", "UCP1301 RCV ON", "EAR Pin", "Ext Ear", "UCP1301 RCV";
			status = "okay";

			sprd-audio-card,dai-link@53 {
				be-id = <0x0>;
				dai-format = "i2s";
				dpcm-playback = <0x1>;
				ignore-suspend = <0x1>;
				link-name = "BE_NORMAL_AP01_UCPSPK";
				no-pcm = <0x1>;
				stream-name = "BE_ST_NORMAL_AP01_UCPSPK";

				codec {
					sound-dai = <0x8 0x0>;
				};

				cpu {
					sound-dai = <0xffffffff 0x1f>;
				};

				plat {
					sound-dai = <0xffffffff>;
				};
			};

			sprd-audio-card,dai-link@55 {
				be-id = <0x0>;
				dai-format = "i2s";
				dpcm-playback = <0x1>;
				ignore-suspend = <0x1>;
				link-name = "BE_NORMAL_AP01_UCPRCV";
				no-pcm = <0x1>;
				stream-name = "BE_ST_NORMAL_AP01_UCPRCV";

				codec {
					sound-dai = <0x9 0x0>;
				};

				cpu {
					sound-dai = <0xffffffff 0x1f>;
				};

				plat {
					sound-dai = <0xffffffff>;
				};
			};

			sprd-audio-card,dai-link@81 {
				be-id = <0x0>;
				dpcm-capture = <0x1>;
				ignore-suspend = <0x1>;
				link-name = "BE_PDM_DMIC";
				no-pcm = <0x1>;
				stream-name = "BE_ST_PDM_DMIC";

				codec {
					sound-dai = <0xffffffff 0x0>;
				};

				cpu {
					sound-dai = <0xffffffff 0x1f>;
				};

				plat {
					sound-dai = <0xffffffff>;
				};
			};
		};
	};

	fragment@23 {
		target = <0xffffffff>;

		__overlay__ {
			regulator-always-on;
		};
	};

	fragment@24 {
		target = <0xffffffff>;

		__overlay__ {
			first-calib-capacity = <0x32>;
			first-calib-voltage = <0x36a060>;
			monitored-battery = <0x2>;
			sprd,calib-resistance-real = <0x12f2>;
			sprd,calib-resistance-spec = <0x4e20>;
		};
	};

	fragment@25 {
		target = <0xffffffff>;

		__overlay__ {
			avdd-gpio = <0xffffffff 0x87 0x0>;
			avee-gpio = <0xffffffff 0x88 0x0>;
			reset-gpio = <0xffffffff 0x32 0x0>;
			sprd,backlight = <0xa>;
		};
	};

	fragment@26 {
		target = <0xffffffff>;

		__overlay__ {
			sprd,backlight = <0xa>;
			sprd,logo-memory = <0xb>;
			sprd,wb-memory = <0xc>;
		};
	};

	fragment@27 {
		target = <0xffffffff>;

		__overlay__ {
			phys = <0xffffffff>;
			sprd,input-voltage-microvolt = <0x4c4b40>;
		};
	};

	fragment@28 {
		target = <0xffffffff>;

		__overlay__ {
			status = "okay";

			connector {
				compatible = "usb-c-connector";
				label = "USB-C";
				op-sink-microwatt = <0x989680>;
				phandle = <0x25>;
				power-role = "dual";
				sink-pdos = <0x40190c8 0xc0dc213c>;
				source-pdos = <0x4019028>;
				try-power-role = "sink";
			};
		};
	};

	fragment@29 {
		target = <0xffffffff>;

		__overlay__ {
			sprd-freq = <0x535 0x300 0x100 0x535 0x535 0xbacd 0x535>;
			sprd-scene = "boost", "lcdon", "lcdoff", "camlow", "camhigh", "camveryhigh", "faceid";
		};
	};

	fragment@3 {
		target = <0xffffffff>;

		__overlay__ {

			board-thmzone {
				phandle = <0x19>;
				polling-delay = <0x0>;
				polling-delay-passive = <0x0>;
				thermal-sensors = <0x3>;
			};

			chg-thmzone {
				phandle = <0x1b>;
				polling-delay = <0x0>;
				polling-delay-passive = <0x0>;
				thermal-sensors = <0x5>;
			};

			pa-thmzone {
				phandle = <0x1a>;
				polling-delay = <0x0>;
				polling-delay-passive = <0x0>;
				thermal-sensors = <0x4>;
			};
		};
	};

	fragment@30 {
		target = <0xffffffff>;

		__overlay__ {
			pinctrl-0 = <0xd>;
			pinctrl-1 = <0xe>;
			pinctrl-2 = <0xf>;
			pinctrl-3 = <0x10>;
			pinctrl-4 = <0x11>;
			pinctrl-5 = <0x12>;
			pinctrl-6 = <0x13>;
			pinctrl-names = "gpio_8", "gpio_22", "gpio_24", "gpio_25", "gpio_26", "gpio_124", "gpio_175";

			bt_rfctl2 {
				function = "func4";
				phandle = <0x13>;
				pins = "QOGIRL6_BT_RFCTL2";
			};

			keyin0 {
				function = "func4";
				phandle = <0x12>;
				pins = "QOGIRL6_KEYIN0";
			};

			rfctl16 {
				function = "func4";
				phandle = <0xd>;
				pins = "QOGIRL6_RFCTL16";
			};

			rfctl3 {
				function = "func4";
				phandle = <0xe>;
				pins = "QOGIRL6_RFCTL3";
			};

			rfctl5 {
				function = "func4";
				phandle = <0xf>;
				pins = "QOGIRL6_RFCTL5";
			};

			rfctl6 {
				function = "func4";
				phandle = <0x10>;
				pins = "QOGIRL6_RFCTL6";
			};

			rfctl7 {
				function = "func4";
				phandle = <0x11>;
				pins = "QOGIRL6_RFCTL7";
			};
		};
	};

	fragment@31 {
		target = <0xffffffff>;

		__overlay__ {

			heap@4 {
				label = "carveout_fd";
				memory-region = <0x14>;
				reg = <0x4>;
				type = <0x2>;
			};
		};
	};

	fragment@32 {
		target = <0xffffffff>;

		__overlay__ {
			sprd,hw-channels = <0x2 0x18cc 0x3 0x18cc 0xd 0x1854 0xf 0x1874 0x11 0x1844 0x13 0x1844 0x15 0x1864 0x1e 0x1820 0x23 0x19b8 0x27 0x19ac>;
		};
	};

	fragment@4 {
		target = <0xffffffff>;

		__overlay__ {
			clock-frequency = <0x61a80>;
			status = "okay";

			sensor-main@20 {
				clock-names = "clk_src", "sensor_eb", "clk_96m", "clk_76m8", "clk_48m", "clk_26m";
				clocks = <0xffffffff 0x2 0xffffffff 0xd 0xffffffff 0x4 0xffffffff 0x10 0xffffffff 0x5 0xffffffff>;
				compatible = "sprd,sensor-main";
				csi = <0xffffffff>;
				dvdd-gpios = <0xffffffff 0x89 0x0>;
				phandle = <0x1c>;
				power-down-gpios = <0xffffffff 0x2f 0x0>;
				reg = <0x20>;
				reset-gpios = <0xffffffff 0x2d 0x0>;
				sprd,phyid = <0x0>;
				vddcama-supply = <0xffffffff>;
				vddcammot-supply = <0xffffffff>;
				vddio-supply = <0xffffffff>;
			};

			sensor-sub@5a {
				clock-names = "clk_src", "sensor_eb", "clk_96m", "clk_76m8", "clk_48m", "clk_26m";
				clocks = <0xffffffff 0x2 0xffffffff 0xd 0xffffffff 0x4 0xffffffff 0x10 0xffffffff 0x5 0xffffffff>;
				compatible = "sprd,sensor-sub";
				csi = <0xffffffff>;
				dvdd-gpios = <0xffffffff 0x89 0x0>;
				phandle = <0x1d>;
				power-down-gpios = <0xffffffff 0x2e 0x0>;
				reg = <0x5a>;
				reset-gpios = <0xffffffff 0x2c 0x0>;
				sprd,phyid = <0x2>;
				vddcama-supply = <0xffffffff>;
				vddcammot-supply = <0xffffffff>;
				vddio-supply = <0xffffffff>;
			};
		};
	};

	fragment@5 {
		target = <0xffffffff>;

		__overlay__ {
			clock-frequency = <0x61a80>;
			status = "okay";

			sensor-main2@20 {
				clock-names = "clk_src", "sensor_eb", "clk_96m", "clk_76m8", "clk_48m", "clk_26m";
				clocks = <0xffffffff 0x3 0xffffffff 0xc 0xffffffff 0x4 0xffffffff 0x10 0xffffffff 0x5 0xffffffff>;
				compatible = "sprd,sensor-main2";
				csi = <0xffffffff>;
				mot-gpios = <0xffffffff 0x71 0x0>;
				phandle = <0x1e>;
				power-down-gpios = <0xffffffff 0x28 0x0>;
				reg = <0x20>;
				reset-gpios = <0xffffffff 0x29 0x0>;
				sprd,phyid = <0x4>;
				vddcama-supply = <0xffffffff>;
				vddcamd-supply = <0xffffffff>;
				vddcammot-supply = <0xffffffff>;
				vddio-supply = <0xffffffff>;
			};
		};
	};

	fragment@6 {
		target = <0xffffffff>;

		__overlay__ {
			clock-frequency = <0x61a80>;
			status = "okay";

			charger@1b {
				chg_pump_en_gpio = <0xffffffff 0x93 0x0>;
				compatible = "halo,hl1506_cp_converter";
				phandle = <0x21>;
				reg = <0x1b>;
			};

			charger@61 {
				compatible = "nuvolta,wl_charger_nu1619";
				phandle = <0x22>;
				phys = <0xffffffff>;
				reg = <0x61>;
				rx,irq_gpio = <0xffffffff 0x92 0x1>;
				switch_chg_en_gpio = <0xffffffff 0xab 0x0>;
				switch_flag_en_gpio = <0xffffffff 0xb0 0x0>;
			};

			charger@65 {
				compatible = "ti,bq2597x-standalone";
				irq-gpio = <0xffffffff 0x7e 0x1>;
				phandle = <0x20>;
				reg = <0x65>;
				ti,bq2597x,ac-ovp-threshold = <0xb>;
				ti,bq2597x,adc-sample-bits = <0xd>;
				ti,bq2597x,bat-ocp-alarm-threshold = <0x1388>;
				ti,bq2597x,bat-ocp-threshold = <0x157c>;
				ti,bq2597x,bat-ovp-alarm-threshold = <0x10f4>;
				ti,bq2597x,bat-ovp-threshold = <0x1130>;
				ti,bq2597x,bat-therm-threshold = <0x15>;
				ti,bq2597x,bat-ucp-alarm-threshold = <0x3e8>;
				ti,bq2597x,bus-ocp-alarm-threshold = <0xa8c>;
				ti,bq2597x,bus-ocp-threshold = <0xbb8>;
				ti,bq2597x,bus-ovp-alarm-threshold = <0x2904>;
				ti,bq2597x,bus-ovp-threshold = <0x2cec>;
				ti,bq2597x,bus-therm-disable = <0x1>;
				ti,bq2597x,bus-therm-threshold = <0x15>;
				ti,bq2597x,die-therm-threshold = <0xc8>;
				ti,bq2597x,ibat-regulation-threshold = <0x12c>;
				ti,bq2597x,regulation-disable = <0x1>;
				ti,bq2597x,sense-resistor-mohm = <0x5>;
				ti,bq2597x,ss-timeout = <0x186a0>;
				ti,bq2597x,vbat-regulation-threshold = <0x64>;
				ti,bq2597x,vdrop-deglitch = <0x1388>;
				ti,bq2597x,vdrop-threshold = <0x190>;
				ti,bq2597x,watchdog-timer = <0x7530>;
			};

			charger@6b {
				compatible = "ti,bq2560x_chg";
				extcon = <0xffffffff 0xffffffff>;
				irq-gpio = <0xffffffff 0x73 0x1>;
				monitored-battery = <0x2>;
				pd-extcon-enable;
				phandle = <0x1f>;
				phys = <0xffffffff>;
				reg = <0x6b>;

				otg-vbus {
					phandle = <0x6>;
					regulator-name = "vddvbus";
				};
			};

			flash-ic@63 {
				compatible = "sprd,flash-ocp8137";
				flash-chip-en-gpios = <0xffffffff 0x8a 0x0>;
				flash-en-gpios = <0xffffffff 0x8b 0x0>;
				flash-sync-gpios = <0xffffffff 0x79 0x0>;
				flash-torch-en-gpios = <0xffffffff 0x20 0x0>;
				phandle = <0x23>;
				reg = <0x63>;
				sprd,flash-ic = <0x1fc9>;
				sprd,highlight = <0x1>;
				sprd,highlight-level = <0x80>;
				sprd,lvfm-enable = <0x1>;
				sprd,preflash = <0x1>;
				sprd,preflash-level = <0x80>;
				sprd,torch = <0x1>;
				sprd,torch-level = <0x80>;
			};
		};
	};

	fragment@7 {
		target = <0xffffffff>;

		__overlay__ {
			clock-frequency = <0x61a80>;
			status = "okay";

			sensor-sub2@6e {
				avdd-gpios = <0xffffffff 0x82 0x0>;
				clock-names = "clk_src", "sensor_eb", "clk_96m", "clk_76m8", "clk_48m", "clk_26m";
				clocks = <0xffffffff 0x4 0xffffffff 0xb 0xffffffff 0x4 0xffffffff 0x10 0xffffffff 0x5 0xffffffff>;
				compatible = "sprd,sensor-sub2";
				csi = <0xffffffff>;
				mot-gpios = <0xffffffff 0x70 0x0>;
				phandle = <0x24>;
				reg = <0x6e>;
				reset-gpios = <0xffffffff 0x72 0x0>;
				sprd,phyid = <0x3>;
				vddcamd-supply = <0xffffffff>;
				vddcammot-supply = <0xffffffff>;
				vddio-supply = <0xffffffff>;
			};
		};
	};

	fragment@8 {
		target = <0xffffffff>;

		__overlay__ {
			clock-frequency = <0xf4240>;
			status = "okay";
		};
	};

	fragment@9 {
		target = <0xffffffff>;

		__overlay__ {
			status = "okay";

			focaltech@0 {
				compatible = "focaltech,fts";
				focaltech,display-coords = <0x0 0x0 0x438 0x960>;
				focaltech,irq-gpio = <0xffffffff 0x90 0x0>;
				focaltech,max-touch-number = <0x5>;
				focaltech,reset-gpio = <0xffffffff 0x91 0x0>;
				reg = <0x0>;
				spi-max-frequency = <0x5b8d80>;
			};
		};
	};

	lcds {

		lcd_dummy_mipi_hd {
			phandle = <0x17>;
			sleep-in = [13 0a 00 01 28 13 78 00 01 10];
			sleep-out = [13 78 00 01 11 13 64 00 01 29];
			sprd,lcd-id-tokernel = <0xffff>;
			sprd,lcd_buildin_name = "lcd_dummy_mipi_hd";

			display-timings {

				timing0 {
					clock-frequency = <0x493e000>;
					hback-porch = <0x3c>;
					hfront-porch = <0x50>;
					hsync-len = <0x3c>;
					phandle = <0x18>;
					sprd,phy-bit-clock = <0x9c400>;
					vback-porch = <0xc>;
					vfront-porch = <0x26>;
					vsync-len = <0x4>;
				};
			};

			lcm@0 {
				init-data = [13 78 00 01 11 13 64 00 01 29];
				lcm_ic_vendor = "dummy";
			};
		};
	};
};
